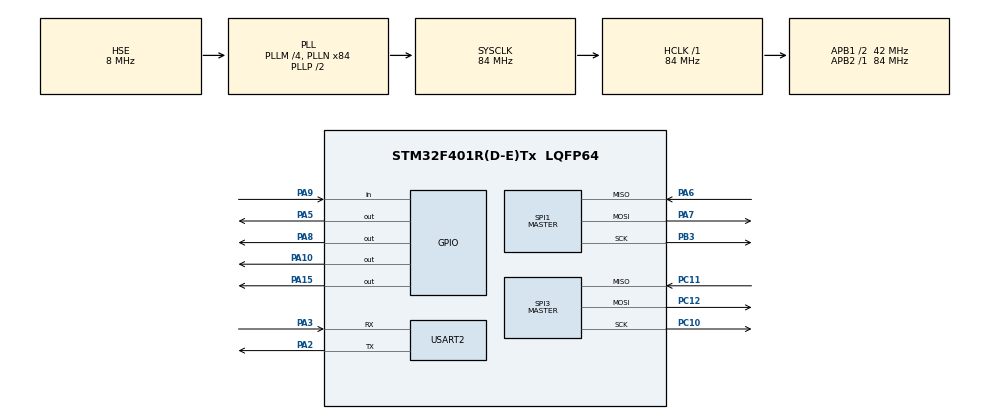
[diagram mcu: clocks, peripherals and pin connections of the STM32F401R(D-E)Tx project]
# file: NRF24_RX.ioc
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Mcu.Family=STM32F4
Mcu.Name=STM32F401R(D-E)Tx
Mcu.Package=LQFP64
NVIC.PriorityGroup=NVIC_PRIORITYGROUP_4
PA10.Signal=GPIO_Output
PA13.Mode=Serial_Wire
PA13.Signal=SYS_JTMS-SWDIO
PA14.Mode=Serial_Wire
PA14.Signal=SYS_JTCK-SWCLK
PA15.Signal=GPIO_Output
PA2.Mode=Asynchronous
PA2.Signal=USART2_TX
PA3.Mode=Asynchronous
PA3.Signal=USART2_RX
PA5.Signal=GPIO_Output
PA6.Mode=Full_Duplex_Master
PA6.Signal=SPI1_MISO
PA7.Mode=Full_Duplex_Master
PA7.Signal=SPI1_MOSI
PA8.Signal=GPIO_Output
PA9.Signal=GPIO_Input
PB3.Mode=Full_Duplex_Master
PB3.Signal=SPI1_SCK
PC10.Mode=Full_Duplex_Master
PC10.Signal=SPI3_SCK
PC11.Mode=Full_Duplex_Master
PC11.Signal=SPI3_MISO
PC12.Mode=Full_Duplex_Master
PC12.Signal=SPI3_MOSI
PH0\ -\ OSC_IN.Mode=HSE-External-Clock-Source
PH0\ -\ OSC_IN.Signal=RCC_OSC_IN
PH1\ -\ OSC_OUT.Mode=HSE-External-Clock-Source
PH1\ -\ OSC_OUT.Signal=RCC_OSC_OUT
ProjectManager.HeapSize=0x200
ProjectManager.StackSize=0x400
ProjectManager.TargetToolchain=MDK-ARM V5
RCC.48MHZClocksFreq_Value=42000000
RCC.AHBFreq_Value=84000000
RCC.APB1CLKDivider=RCC_HCLK_DIV2
RCC.APB1Freq_Value=42000000
RCC.APB1TimFreq_Value=84000000
RCC.APB2Freq_Value=84000000
RCC.APB2TimFreq_Value=84000000
RCC.CortexFreq_Value=84000000
RCC.HCLKFreq_Value=84000000
RCC.HSE_VALUE=8000000
RCC.HSI_VALUE=16000000
RCC.LSE_VALUE=32768
RCC.PLLM=4
RCC.PLLN=84
RCC.PLLSourceVirtual=RCC_PLLSOURCE_HSE
RCC.SYSCLKFreq_VALUE=84000000
RCC.SYSCLKSource=RCC_SYSCLKSOURCE_PLLCLK
RCC.VCOOutputFreq_Value=168000000
SPI1.BaudRatePrescaler=SPI_BAUDRATEPRESCALER_16
SPI1.Direction=SPI_DIRECTION_2LINES
SPI1.Mode=SPI_MODE_MASTER
SPI1.VirtualType=VM_MASTER
SPI3.BaudRatePrescaler=SPI_BAUDRATEPRESCALER_16
SPI3.Direction=SPI_DIRECTION_2LINES
SPI3.Mode=SPI_MODE_MASTER
SPI3.VirtualType=VM_MASTER
USART2.VirtualMode=VM_ASYNC
board=NRF24_RX

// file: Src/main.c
/**
  ******************************************************************************
  * File Name          : main.c
  * Description        : Main program body
  ******************************************************************************
  ** This notice applies to any and all portions of this file
  * that are not between comment pairs USER CODE BEGIN and
  * USER CODE END. Other portions of this file, whether
  * inserted by the user or by software development tools
  * are owned by their respective copyright owners.
  *
  * COPYRIGHT(c) 2018 STMicroelectronics
  *
  * Redistribution and use in source and binary forms, with or without modification,
  * are permitted provided that the following conditions are met:
  *   1. Redistributions of source code must retain the above copyright notice,
  *      this list of conditions and the following disclaimer.
  *   2. Redistributions in binary form must reproduce the above copyright notice,
  *      this list of conditions and the following disclaimer in the documentation
  *      and/or other materials provided with the distribution.
  *   3. Neither the name of STMicroelectronics nor the names of its contributors
  *      may be used to endorse or promote products derived from this software
  *      without specific prior written permission.
  *
  * THIS SOFTWARE IS PROVIDED BY THE COPYRIGHT HOLDERS AND CONTRIBUTORS "AS IS"
  * AND ANY EXPRESS OR IMPLIED WARRANTIES, INCLUDING, BUT NOT LIMITED TO, THE
  * IMPLIED WARRANTIES OF MERCHANTABILITY AND FITNESS FOR A PARTICULAR PURPOSE ARE
  * DISCLAIMED. IN NO EVENT SHALL THE COPYRIGHT HOLDER OR CONTRIBUTORS BE LIABLE
  * FOR ANY DIRECT, INDIRECT, INCIDENTAL, SPECIAL, EXEMPLARY, OR CONSEQUENTIAL
  * DAMAGES (INCLUDING, BUT NOT LIMITED TO, PROCUREMENT OF SUBSTITUTE GOODS OR
  * SERVICES; LOSS OF USE, DATA, OR PROFITS; OR BUSINESS INTERRUPTION) HOWEVER
  * CAUSED AND ON ANY THEORY OF LIABILITY, WHETHER IN CONTRACT, STRICT LIABILITY,
  * OR TORT (INCLUDING NEGLIGENCE OR OTHERWISE) ARISING IN ANY WAY OUT OF THE USE
  * OF THIS SOFTWARE, EVEN IF ADVISED OF THE POSSIBILITY OF SUCH DAMAGE.
  *
  ******************************************************************************
  */
#include "main.h"
#include "stm32f4xx_hal.h"

/* USER CODE BEGIN Includes */
#include "NRF24.h"
#include "max7219.h"
#include <string.h>
/* USER CODE END Includes */

SPI_HandleTypeDef hspi1;
SPI_HandleTypeDef hspi3;

UART_HandleTypeDef huart2;

/* USER CODE BEGIN PV */
/* Private variables ---------------------------------------------------------*/
char str1[150]={0};
uint8_t buf1[20]={0};
/* USER CODE END PV */

void SystemClock_Config(void);
static void MX_GPIO_Init(void);
static void MX_USART2_UART_Init(void);
static void MX_SPI1_Init(void);
static void MX_SPI3_Init(void);

/* USER CODE BEGIN PFP */
/* Private function prototypes -----------------------------------------------*/

/* USER CODE END PFP */

int main(void)
{

  /* MCU Configuration----------------------------------------------------------*/

  /* Reset of all peripherals, Initializes the Flash interface and the Systick. */
  HAL_Init();

  /* Configure the system clock */
  SystemClock_Config();

  /* Initialize all configured peripherals */
  MX_GPIO_Init();
  MX_USART2_UART_Init();
  MX_SPI1_Init();
  MX_SPI3_Init();

  /* USER CODE BEGIN 2 */
	HAL_Delay(200);
	Init_7219();
	HAL_Delay(200);
	NRF24_ini();
	Clear_7219();
  /* USER CODE END 2 */

  /* Infinite loop */
  while (1)
  {

  /* USER CODE BEGIN 3 */
		NRF24L01_Receive();
  }
  /* USER CODE END 3 */

}

/** System Clock Configuration
*/
void SystemClock_Config(void)
{

  RCC_OscInitTypeDef RCC_OscInitStruct;
  RCC_ClkInitTypeDef RCC_ClkInitStruct;

    /**Configure the main internal regulator output voltage
    */
  __HAL_RCC_PWR_CLK_ENABLE();

  __HAL_PWR_VOLTAGESCALING_CONFIG(PWR_REGULATOR_VOLTAGE_SCALE2);

    /**Initializes the CPU, AHB and APB busses clocks
    */
  RCC_OscInitStruct.OscillatorType = RCC_OSCILLATORTYPE_HSE;
  RCC_OscInitStruct.HSEState = RCC_HSE_BYPASS;
  RCC_OscInitStruct.PLL.PLLState = RCC_PLL_ON;
  RCC_OscInitStruct.PLL.PLLSource = RCC_PLLSOURCE_HSE;
  RCC_OscInitStruct.PLL.PLLM = 4;
  RCC_OscInitStruct.PLL.PLLN = 84;
  RCC_OscInitStruct.PLL.PLLP = RCC_PLLP_DIV2;
  RCC_OscInitStruct.PLL.PLLQ = 4;
  if (HAL_RCC_OscConfig(&RCC_OscInitStruct) != HAL_OK)
  {
    _Error_Handler(__FILE__, __LINE__);
  }

    /**Initializes the CPU, AHB and APB busses clocks
    */
  RCC_ClkInitStruct.ClockType = RCC_CLOCKTYPE_HCLK|RCC_CLOCKTYPE_SYSCLK
                              |RCC_CLOCKTYPE_PCLK1|RCC_CLOCKTYPE_PCLK2;
  RCC_ClkInitStruct.SYSCLKSource = RCC_SYSCLKSOURCE_PLLCLK;
  RCC_ClkInitStruct.AHBCLKDivider = RCC_SYSCLK_DIV1;
  RCC_ClkInitStruct.APB1CLKDivider = RCC_HCLK_DIV2;
  RCC_ClkInitStruct.APB2CLKDivider = RCC_HCLK_DIV1;

  if (HAL_RCC_ClockConfig(&RCC_ClkInitStruct, FLASH_LATENCY_2) != HAL_OK)
  {
    _Error_Handler(__FILE__, __LINE__);
  }

    /**Configure the Systick interrupt time
    */
  HAL_SYSTICK_Config(HAL_RCC_GetHCLKFreq()/1000);

    /**Configure the Systick
    */
  HAL_SYSTICK_CLKSourceConfig(SYSTICK_CLKSOURCE_HCLK);

  /* SysTick_IRQn interrupt configuration */
  HAL_NVIC_SetPriority(SysTick_IRQn, 0, 0);
}

/* SPI1 init function */
static void MX_SPI1_Init(void)
{

  /* SPI1 parameter configuration*/
  hspi1.Instance = SPI1;
  hspi1.Init.Mode = SPI_MODE_MASTER;
  hspi1.Init.Direction = SPI_DIRECTION_2LINES;
  hspi1.Init.DataSize = SPI_DATASIZE_8BIT;
  hspi1.Init.CLKPolarity = SPI_POLARITY_LOW;
  hspi1.Init.CLKPhase = SPI_PHASE_1EDGE;
  hspi1.Init.NSS = SPI_NSS_SOFT;
  hspi1.Init.BaudRatePrescaler = SPI_BAUDRATEPRESCALER_16;
  hspi1.Init.FirstBit = SPI_FIRSTBIT_MSB;
  hspi1.Init.TIMode = SPI_TIMODE_DISABLE;
  hspi1.Init.CRCCalculation = SPI_CRCCALCULATION_DISABLE;
  hspi1.Init.CRCPolynomial = 10;
  if (HAL_SPI_Init(&hspi1) != HAL_OK)
  {
    _Error_Handler(__FILE__, __LINE__);
  }

}

/* SPI3 init function */
static void MX_SPI3_Init(void)
{

  /* SPI3 parameter configuration*/
  hspi3.Instance = SPI3;
  hspi3.Init.Mode = SPI_MODE_MASTER;
  hspi3.Init.Direction = SPI_DIRECTION_2LINES;
  hspi3.Init.DataSize = SPI_DATASIZE_8BIT;
  hspi3.Init.CLKPolarity = SPI_POLARITY_LOW;
  hspi3.Init.CLKPhase = SPI_PHASE_1EDGE;
  hspi3.Init.NSS = SPI_NSS_SOFT;
  hspi3.Init.BaudRatePrescaler = SPI_BAUDRATEPRESCALER_16;
  hspi3.Init.FirstBit = SPI_FIRSTBIT_MSB;
  hspi3.Init.TIMode = SPI_TIMODE_DISABLE;
  hspi3.Init.CRCCalculation = SPI_CRCCALCULATION_DISABLE;
  hspi3.Init.CRCPolynomial = 10;
  if (HAL_SPI_Init(&hspi3) != HAL_OK)
  {
    _Error_Handler(__FILE__, __LINE__);
  }

}

/* USART2 init function */
static void MX_USART2_UART_Init(void)
{

  huart2.Instance = USART2;
  huart2.Init.BaudRate = 115200;
  huart2.Init.WordLength = UART_WORDLENGTH_8B;
  huart2.Init.StopBits = UART_STOPBITS_1;
  huart2.Init.Parity = UART_PARITY_NONE;
  huart2.Init.Mode = UART_MODE_TX_RX;
  huart2.Init.HwFlowCtl = UART_HWCONTROL_NONE;
  huart2.Init.OverSampling = UART_OVERSAMPLING_16;
  if (HAL_UART_Init(&huart2) != HAL_OK)
  {
    _Error_Handler(__FILE__, __LINE__);
  }

}

/** Configure pins as
        * Analog
        * Input
        * Output
        * EVENT_OUT
        * EXTI
*/
static void MX_GPIO_Init(void)
{

  GPIO_InitTypeDef GPIO_InitStruct;

  /* GPIO Ports Clock Enable */
  __HAL_RCC_GPIOH_CLK_ENABLE();
  __HAL_RCC_GPIOA_CLK_ENABLE();
  __HAL_RCC_GPIOC_CLK_ENABLE();
  __HAL_RCC_GPIOB_CLK_ENABLE();

  /*Configure GPIO pin Output Level */
  HAL_GPIO_WritePin(GPIOA, GPIO_PIN_5|GPIO_PIN_8|GPIO_PIN_10|GPIO_PIN_15, GPIO_PIN_RESET);

  /*Configure GPIO pins : PA5 PA8 PA10 PA15 */
  GPIO_InitStruct.Pin = GPIO_PIN_5|GPIO_PIN_8|GPIO_PIN_10|GPIO_PIN_15;
  GPIO_InitStruct.Mode = GPIO_MODE_OUTPUT_PP;
  GPIO_InitStruct.Pull = GPIO_NOPULL;
  GPIO_InitStruct.Speed = GPIO_SPEED_FREQ_LOW;
  HAL_GPIO_Init(GPIOA, &GPIO_InitStruct);

  /*Configure GPIO pin : PA9 */
  GPIO_InitStruct.Pin = GPIO_PIN_9;
  GPIO_InitStruct.Mode = GPIO_MODE_INPUT;
  GPIO_InitStruct.Pull = GPIO_NOPULL;
  HAL_GPIO_Init(GPIOA, &GPIO_InitStruct);

}

void _Error_Handler(char * file, int line)
{
  while(1)
  {
  }
}

/************************ (C) COPYRIGHT STMicroelectronics *****END OF FILE****/
